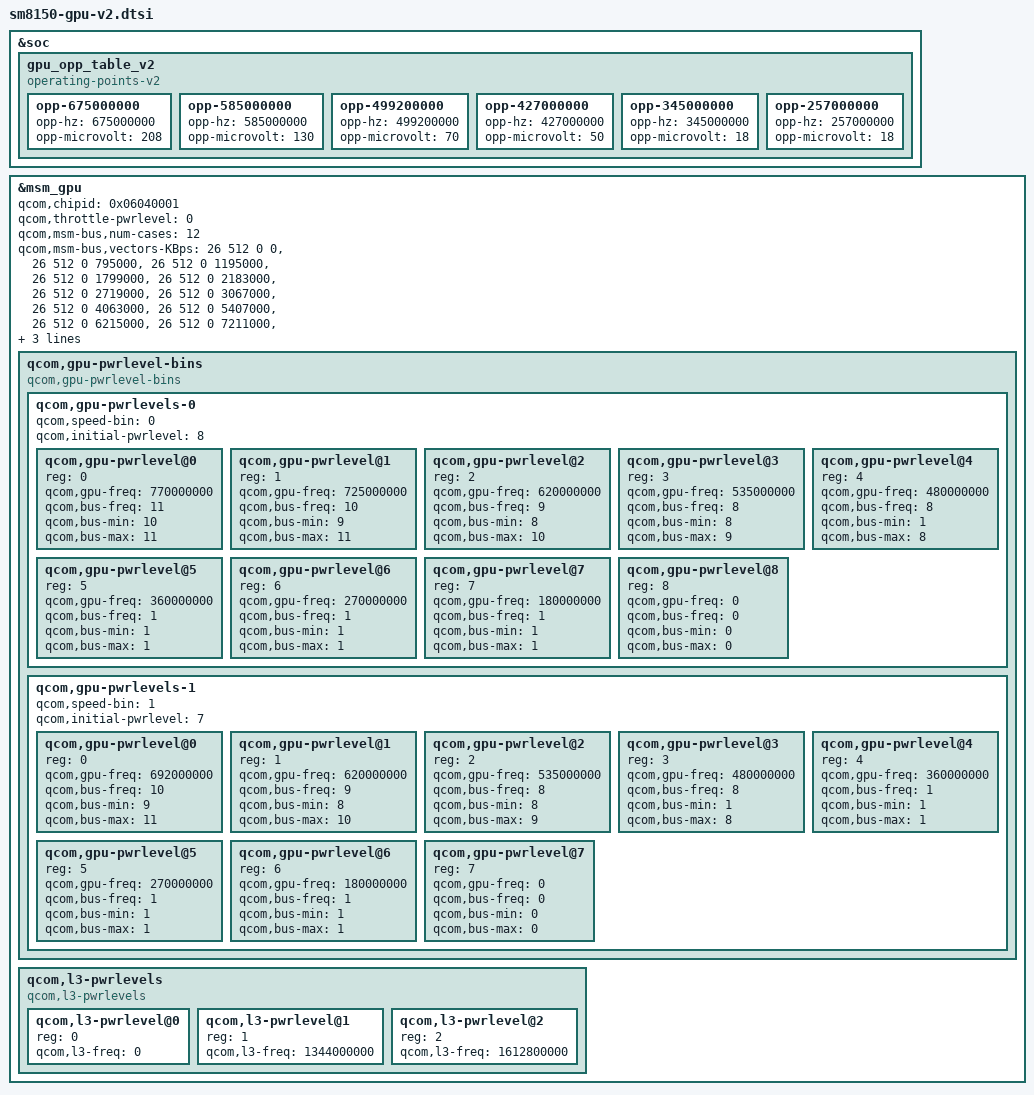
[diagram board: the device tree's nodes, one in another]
&soc {
	gpu_opp_table_v2: gpu_opp_table_v2 {
		compatible = "operating-points-v2";

		opp-675000000 {
			opp-hz = /bits/ 64 <675000000>;
			opp-microvolt = <208>;
		};

		opp-585000000 {
			opp-hz = /bits/ 64 <585000000>;
			opp-microvolt = <130>;
		};

		opp-499200000 {
			opp-hz = /bits/ 64 <499200000>;
			opp-microvolt = <70>;
		};

		opp-427000000 {
			opp-hz = /bits/ 64 <427000000>;
			opp-microvolt = <50>;
		};

		opp-345000000 {
			opp-hz = /bits/ 64 <345000000>;
			opp-microvolt = <18>;
		};

		opp-257000000 {
			opp-hz = /bits/ 64 <257000000>;
			opp-microvolt = <18>;
		};
	};
};

&msm_gpu {
	qcom,chipid = <0x06040001>;

	/* Power level to start throttling */
	qcom,throttle-pwrlevel = <0>;

	/* Updated Bus Scale Settings */
	qcom,msm-bus,num-cases = <12>;

	/*
	 * Value for vote is: (DDR freq) * 4 - 5
	 * The 5 value is to ensure that there is no rounding errors
	 * where the total request doesn't divide evenly by the BCM
	 * DDR bandwidth unit (note, 5 is greater than this unit).
	 */
	qcom,msm-bus,vectors-KBps =
		<26 512 0 0>,          // 0 bus=0
		<26 512 0 795000>,     // 1 bus=200
		<26 512 0 1195000>,    // 2 bus=300
		<26 512 0 1799000>,    // 3 bus=451
		<26 512 0 2183000>,    // 4 bus=547
		<26 512 0 2719000>,    // 5 bus=681
		<26 512 0 3067000>,    // 6 bus=768
		<26 512 0 4063000>,    // 7 bus=1017
		<26 512 0 5407000>,    // 8 bus=1353
		<26 512 0 6215000>,    // 9 bus=1555
		<26 512 0 7211000>,    // 10 bus=1804
		<26 512 0 8363000>;    // 11 bus=2092

	/delete-property/qcom,initial-pwrlevel;

	operating-points-v2 = <&gpu_opp_table_v2>;

	qcom,gpu-speed-bin = <0x4130 0xe0000000 29>;

	/delete-node/qcom,gpu-pwrlevels;
	qcom,gpu-pwrlevel-bins {
		#address-cells = <1>;
		#size-cells = <0>;

		compatible="qcom,gpu-pwrlevel-bins";
		qcom,gpu-pwrlevels-0 {
			#address-cells = <1>;
			#size-cells = <0>;

			qcom,speed-bin = <0>;
			qcom,initial-pwrlevel = <8>;

			qcom,gpu-pwrlevel@0 {
				reg = <0>;
				qcom,gpu-freq = <770000000>;
				qcom,bus-freq = <11>;
				qcom,bus-min = <10>;
				qcom,bus-max = <11>;
			};

			qcom,gpu-pwrlevel@1 {
				reg = <1>;
				qcom,gpu-freq = <725000000>;
				qcom,bus-freq = <10>;
				qcom,bus-min = <9>;
				qcom,bus-max = <11>;
			};

			qcom,gpu-pwrlevel@2 {
				reg = <2>;
				qcom,gpu-freq = <620000000>;
				qcom,bus-freq = <9>;
				qcom,bus-min = <8>;
				qcom,bus-max = <10>;
			};

			qcom,gpu-pwrlevel@3 {
				reg = <3>;
				qcom,gpu-freq = <535000000>;
				qcom,bus-freq = <8>;
				qcom,bus-min = <8>;
				qcom,bus-max = <9>;
			};

			qcom,gpu-pwrlevel@4 {
				reg = <4>;
				qcom,gpu-freq = <480000000>;
				qcom,bus-freq = <8>;
				qcom,bus-min = <1>;
				qcom,bus-max = <8>;
			};

			qcom,gpu-pwrlevel@5 {
				reg = <5>;
				qcom,gpu-freq = <360000000>;
				qcom,bus-freq = <1>;
				qcom,bus-min = <1>;
				qcom,bus-max = <1>;
			};

			qcom,gpu-pwrlevel@6 {
				reg = <6>;
				qcom,gpu-freq = <270000000>;
				qcom,bus-freq = <1>;
				qcom,bus-min = <1>;
				qcom,bus-max = <1>;
			};

			qcom,gpu-pwrlevel@7 {
				reg = <7>;
				qcom,gpu-freq = <180000000>;
				qcom,bus-freq = <1>;
				qcom,bus-min = <1>;
				qcom,bus-max = <1>;
			};

			qcom,gpu-pwrlevel@8 {
				reg = <8>;
				qcom,gpu-freq = <0>;
				qcom,bus-freq = <0>;
				qcom,bus-min = <0>;
				qcom,bus-max = <0>;
			};
		};
		qcom,gpu-pwrlevels-1 {
			#address-cells = <1>;
			#size-cells = <0>;

			qcom,speed-bin = <1>;
			qcom,initial-pwrlevel = <7>;

			qcom,gpu-pwrlevel@0 {
                                reg = <0>;
                                qcom,gpu-freq = <692000000>;
                                qcom,bus-freq = <10>;
                                qcom,bus-min = <9>;
                                qcom,bus-max = <11>;
                        };

			qcom,gpu-pwrlevel@1 {
				reg = <1>;
				qcom,gpu-freq = <620000000>;
				qcom,bus-freq = <9>;
				qcom,bus-min = <8>;
				qcom,bus-max = <10>;
			};

			qcom,gpu-pwrlevel@2 {
				reg = <2>;
				qcom,gpu-freq = <535000000>;
				qcom,bus-freq = <8>;
				qcom,bus-min = <8>;
				qcom,bus-max = <9>;
			};

			qcom,gpu-pwrlevel@3 {
				reg = <3>;
				qcom,gpu-freq = <480000000>;
				qcom,bus-freq = <8>;
				qcom,bus-min = <1>;
				qcom,bus-max = <8>;
			};

			qcom,gpu-pwrlevel@4 {
				reg = <4>;
				qcom,gpu-freq = <360000000>;
				qcom,bus-freq = <1>;
				qcom,bus-min = <1>;
				qcom,bus-max = <1>;
			};

			qcom,gpu-pwrlevel@5 {
				reg = <5>;
				qcom,gpu-freq = <270000000>;
				qcom,bus-freq = <1>;
				qcom,bus-min = <1>;
				qcom,bus-max = <1>;
			};

			qcom,gpu-pwrlevel@6 {
                                reg = <6>;
                                qcom,gpu-freq = <180000000>;
                                qcom,bus-freq = <1>;
                                qcom,bus-min = <1>;
                                qcom,bus-max = <1>;
                        };

			qcom,gpu-pwrlevel@7 {
				reg = <7>;
				qcom,gpu-freq = <0>;
				qcom,bus-freq = <0>;
				qcom,bus-min = <0>;
				qcom,bus-max = <0>;
			};
		};
	};

	qcom,l3-pwrlevels {
		#address-cells = <1>;
		#size-cells = <0>;

		compatible = "qcom,l3-pwrlevels";

		qcom,l3-pwrlevel@0 {
			reg = <0>;
			qcom,l3-freq = <0>;
		};

		qcom,l3-pwrlevel@1 {
			reg = <1>;
			qcom,l3-freq = <1344000000>;
		};

		qcom,l3-pwrlevel@2 {
			reg = <2>;
			qcom,l3-freq = <1612800000>;
		};
	};
};
